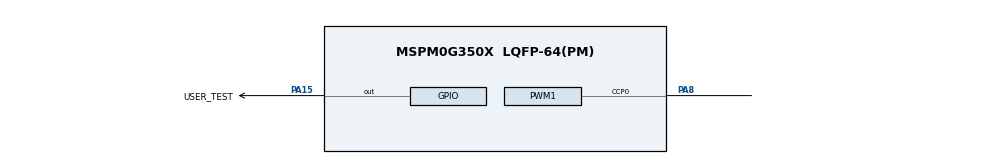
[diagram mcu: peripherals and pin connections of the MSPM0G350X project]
/**
 * @cliArgs --device "MSPM0G350X" --package "LQFP-64(PM)" --part "Default" --product "mspm0_sdk@2.01.00.03"
 * @versions {"tool":"1.19.0+3426"}
 */

/**
 * Import the modules used in this configuration.
 */
const GPIO   = scripting.addModule("/ti/driverlib/GPIO", {}, false);
const GPIO1  = GPIO.addInstance();
const PWM    = scripting.addModule("/ti/driverlib/PWM", {}, false);
const PWM1   = PWM.addInstance();
const SYSCTL = scripting.addModule("/ti/driverlib/SYSCTL");

/**
 * Write custom configuration values to the imported modules.
 */
const gate7  = system.clockTree["MFCLKGATE"];
gate7.enable = true;

GPIO1.$name                                 = "GPIO_LEDS";
GPIO1.associatedPins.create(4);
GPIO1.associatedPins[0].assignedPort        = "PORTA";
GPIO1.associatedPins[0].assignedPortSegment = "Lower";
GPIO1.associatedPins[0].$name               = "USER_TEST";
GPIO1.associatedPins[0].initialValue        = "SET";
GPIO1.associatedPins[0].pin.$assign         = "PA15";
GPIO1.associatedPins[1].$name               = "PIN_24";
GPIO1.associatedPins[1].direction           = "INPUT";
GPIO1.associatedPins[1].assignedPort        = "PORTB";
GPIO1.associatedPins[1].assignedPin         = "24";
GPIO1.associatedPins[2].$name               = "LED";
GPIO1.associatedPins[2].assignedPort        = "PORTB";
GPIO1.associatedPins[2].assignedPin         = "27";
GPIO1.associatedPins[3].$name               = "SWITCH_1";
GPIO1.associatedPins[3].direction           = "INPUT";
GPIO1.associatedPins[3].assignedPort        = "PORTA";
GPIO1.associatedPins[3].assignedPin         = "18";

const Board = scripting.addModule("/ti/driverlib/Board", {}, false);

PWM1.$name                          = "PWM_0";
PWM1.dbRiseDelayTimerCount          = 50;
PWM1.dbFallDelayTimerCount          = 25;
PWM1.ccIndex                        = [0];
PWM1.enableShadowLoad               = true;
PWM1.interrupts                     = ["CC0_DN_EVENT"];
PWM1.clockPrescale                  = 40;
PWM1.timerCount                     = 10000;
PWM1.clockSource                    = "LFCLK";
PWM1.peripheral.$assign             = "TIMA0";
PWM1.peripheral.ccp0Pin.$assign     = "PA8";
PWM1.PWM_CHANNEL_0.$name            = "ti_driverlib_pwm_PWMTimerCC0";
PWM1.PWM_CHANNEL_0.shadowUpdateMode = "ZERO_EVT";
PWM1.PWM_CHANNEL_0.dutyCycle        = 50;
PWM1.ccp0PinConfig.$name            = "ti_driverlib_gpio_GPIOPinGeneric0";

SYSCTL.MFCLKEn               = true;
SYSCTL.forceDefaultClkConfig = true;
SYSCTL.clockTreeEn           = true;

/**
 * Pinmux solution for unlocked pins/peripherals. This ensures that minor changes to the automatic solver in a future
 * version of the tool will not impact the pinmux you originally saw.  These lines can be completely deleted in order to
 * re-solve from scratch.
 */
GPIO1.associatedPins[1].pin.$suggestSolution = "PB24";
GPIO1.associatedPins[2].pin.$suggestSolution = "PB27";
GPIO1.associatedPins[3].pin.$suggestSolution = "PA18";
Board.peripheral.$suggestSolution            = "DEBUGSS";
Board.peripheral.swclkPin.$suggestSolution   = "PA20";
Board.peripheral.swdioPin.$suggestSolution   = "PA19";
